# DSS0_WB register map
Vendor: Texas Instruments
Peripheral module from a debugger description file (folder J7ES).
Registers are 32-bit, access per field, reset 0x0 unless marked. A register's access mark holds for its fields unless they carry their own. Offsets are as the file gives them; lines under a group give offsets from that group; [hi:lo] are bit positions; {n}, {i} and the like mark numbered series; 'fields as' and 'values as' point back to an identical list; <NAME> marks a mode.

## DSS0_WB
0x00 DSS0_WB_ACCUH_0 — The register configures the resize accumulator init values for horizontal up/down-sampling of the write-back window. It is used for ARGB and Y setting. Shadow register
  [23:0] HORIZONTALACCU rw — Horizontal initialization accu signed value
0x04 DSS0_WB_ACCUH_1 — The register configures the resize accumulator init values for horizontal up/down-sampling of the write-back window. It is used for ARGB and Y setting. Shadow register
  fields as DSS0_WB_ACCUH_0
0x08 DSS0_WB_ACCUH2_0 — The register configures the resize accumulator init value for horizontal up/down-sampling of the write-back window. It is used for Cb and Cr setting. It is used only when the pixel format at the input of the filter is one of the YUV formats. If the pixel format at the input of the filter is ARGB, all ARGB, RGB, RGBA are converted to ARGB32-8888 by the color space conversion before going to the filter as the color space conversion is done before the filter. When the register is not used by the HW, any value can be used for the bit-fields. Shadow register
  fields as DSS0_WB_ACCUH_0
0x0C DSS0_WB_ACCUH2_1 — The register configures the resize accumulator init value for horizontal up/down-sampling of the write-back window. It is used for Cb and Cr setting. It is used only when the pixel format at the input of the filter is one of the YUV formats. If the pixel format at the input of the filter is ARGB, all ARGB, RGB, RGBA are converted to ARGB32-8888 by the color space conversion before going to the filter as the color space conversion is done before the filter. When the register is not used by the HW, any value can be used for the bit-fields. Shadow register
  fields as DSS0_WB_ACCUH_0
0x10 DSS0_WB_ACCUV_0 — The register configures the resize accumulator init value for vertical up/down-sampling of the write-back window. It is used for ARGB and Y setting. Shadow register
  [23:0] VERTICALACCU rw — Vertical initialization accu signed value
0x14 DSS0_WB_ACCUV_1 — The register configures the resize accumulator init value for vertical up/down-sampling of the write-back window. It is used for ARGB and Y setting. Shadow register
  [23:0] VERTICALACCU rw — Vertical initialization accu signed value
0x18 DSS0_WB_ACCUV2_0 — The register configures the resize accumulator init value for vertical up/down-sampling of the write-back window. It is used for Cb and Cr setting. It is used only when the pixel format at the input of the filter is one of the YUV formats. If the pixel format at the input of the filter is ARGB, all ARGB, RGB, RGBA are converted to ARGB32-8888 by the color space conversion before going to the filter as the color space conversion is done before the filter. When the register is not used by the HW, any value can be used for the bit-fields. Shadow register
  [23:0] VERTICALACCU rw — Vertical initialization accu signed value
0x1C DSS0_WB_ACCUV2_1 — The register configures the resize accumulator init value for vertical up/down-sampling of the write-back window. It is used for Cb and Cr setting. It is used only when the pixel format at the input of the filter is one of the YUV formats. If the pixel format at the input of the filter is ARGB, all ARGB, RGB, RGBA are converted to ARGB32-8888 by the color space conversion before going to the filter as the color space conversion is done before the filter. When the register is not used by the HW, any value can be used for the bit-fields. Shadow register
  [23:0] VERTICALACCU rw — Vertical initialization accu signed value
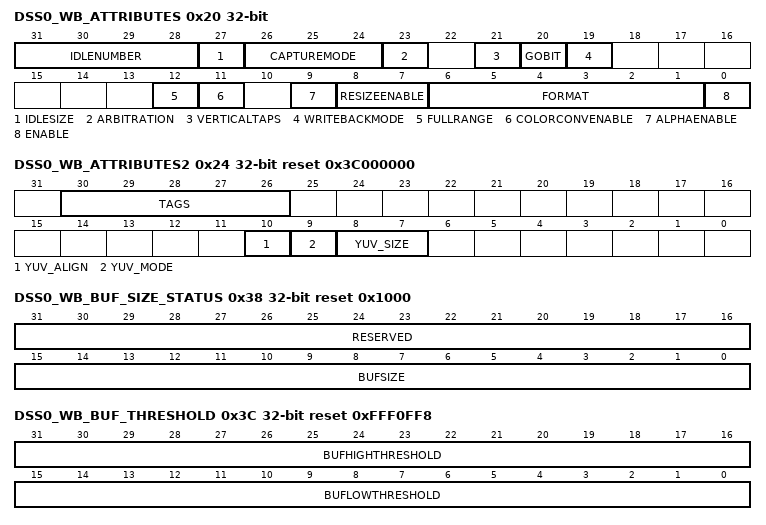
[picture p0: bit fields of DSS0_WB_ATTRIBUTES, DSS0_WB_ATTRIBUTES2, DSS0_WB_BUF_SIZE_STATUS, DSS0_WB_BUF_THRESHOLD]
0x20 DSS0_WB_ATTRIBUTES — The register configures the of the write back pipeline. Shadow register
  [31:28] IDLENUMBER rw — Determines the number of idles between requests on the L3 interconnect.
  [27] IDLESIZE rw — Determines if the IDLENUMBER corresponds to a number of bursts or singles
  [26:24] CAPTUREMODE rw — Defines the frame rate capture
  [23] ARBITRATION rw — Determines the priority of the write-back pipeline.
  [21] VERTICALTAPS rw — Video Vertical Resize Tap Number
  [20] GOBIT rw — GO Command for the WB output.
  [19] WRITEBACKMODE rw — When connected to the overlay output of a channel the write back can operate as a simple transfer from memory to memory [composition engine] or as a capture channel
  [12] FULLRANGE rw — Color Space Conversion full range setting
  [11] COLORCONVENABLE rw — Enable the color space conversion.
  [9] ALPHAENABLE rw — Alpha enable on WB output
  [8:7] RESIZEENABLE rw
  [6:1] FORMAT rw — Write-back Format.
  [0] ENABLE rw — Write-back Enable wr: immediate
0x24 DSS0_WB_ATTRIBUTES2 reset 0x3C000000 — The register configures the of the write back pipeline. Shadow register
  [30:26] TAGS rw — Number of OCP TAGS to be used for the pipeline [0x0 to 0xF].
  [10] YUV_ALIGN rw — Alignment [MSB or LSB align] for unpacked 10b/12b YUV data
  [9] YUV_MODE rw — Mode of packing for YUV data [only for 10b/12b formats]
  [8:7] YUV_SIZE rw
0x28 DSS0_WB_BA_0 rw — The register configures the base address of the WB buffer. DISPC_WB_BA__0 & DISPC_WB_BA__1 for ping-pong mechanism with external trigger, based on the field polarity, otherwise only DISPC_WB_BA__0 is used. Shadow register
  [31:0] BA — Write-back base address Base address of the WB buffer [aligned on pixel
0x2C DSS0_WB_BA_1 rw — The register configures the base address of the WB buffer. DISPC_WB_BA__0 & DISPC_WB_BA__1 for ping-pong mechanism with external trigger, based on the field polarity, otherwise only DISPC_WB_BA__0 is used. Shadow register
  fields as DSS0_WB_BA_0
0x30 DSS0_WB_BA_UV_0 rw — The register configures the base address of the UV buffer for the write-back pipeline. DISPC_WB_BA_UV__0 & DISPC_WB_BA_UV__1 for ping-pong mechanism with external trigger, based on the field polarity, otherwise only DISPC_WB_BA_UV__0 is used. The register is also used to configure the RGB plane BA for RGB565A8 format. Shadow register
  [31:0] BA — WB base address aligned on 16-bit boundary.
0x34 DSS0_WB_BA_UV_1 rw — The register configures the base address of the UV buffer for the write-back pipeline. DISPC_WB_BA_UV__0 & DISPC_WB_BA_UV__1 for ping-pong mechanism with external trigger, based on the field polarity, otherwise only DISPC_WB_BA_UV__0 is used. The register is also used to configure the RGB plane BA for RGB565A8 format. Shadow register
  [31:0] BA — WB base address aligned on 16-bit boundary.
0x38 DSS0_WB_BUF_SIZE_STATUS ro reset 0x1000 — The register defines the DMA buffer for the write back pipeline
  [31:16] RESERVED — Write 0's for future compatibility.
  [15:0] BUFSIZE — DMA buffer
0x3C DSS0_WB_BUF_THRESHOLD rw reset 0xFFF0FF8 — The register configures the DMA buffer associated with the write-back pipeline. Shadow register
  [31:16] BUFHIGHTHRESHOLD — DMA buffer High Threshold Number of
  [15:0] BUFLOWTHRESHOLD — DMA buffer High Threshold Number of
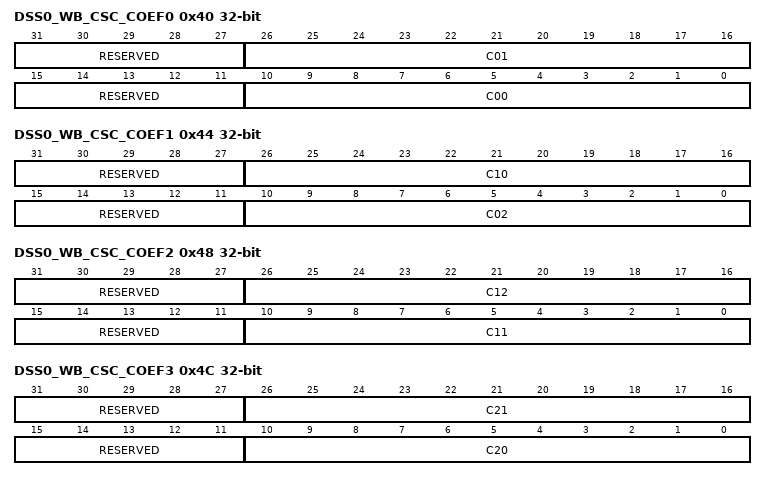
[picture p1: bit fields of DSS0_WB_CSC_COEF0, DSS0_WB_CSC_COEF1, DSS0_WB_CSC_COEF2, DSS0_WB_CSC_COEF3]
0x40 DSS0_WB_CSC_COEF0 — The register configures the color space conversion matrix coefficients. Shadow register
  [31:27] RESERVED ro — Write 0's for future compatibility Reads return 0
  [26:16] C01 rw — C01 Coefficient.
  [15:11] RESERVED ro — Write 0's for future compatibility Reads return 0
  [10:0] C00 rw — C00 Coefficient.
0x44 DSS0_WB_CSC_COEF1 — The register configures the color space conversion matrix coefficients. Shadow register
  [31:27] RESERVED ro — Write 0's for future compatibility Reads return 0
  [26:16] C10 rw — C10 Coefficient.
  [15:11] RESERVED ro — Write 0's for future compatibility Reads return 0
  [10:0] C02 rw — C02 Coefficient.
0x48 DSS0_WB_CSC_COEF2 — The register configures the color space conversion matrix coefficients. Shadow register
  [31:27] RESERVED ro — Write 0's for future compatibility Reads return 0
  [26:16] C12 rw — C12 Coefficient.
  [15:11] RESERVED ro — Write 0's for future compatibility Reads return 0
  [10:0] C11 rw — C11 Coefficient.
0x4C DSS0_WB_CSC_COEF3 — The register configures the color space conversion matrix coefficients. Shadow register
  [31:27] RESERVED ro — Write 0's for future compatibility Reads return 0
  [26:16] C21 rw — C21 coefficient.
  [15:11] RESERVED ro — Write 0's for future compatibility Reads return 0
  [10:0] C20 rw — C20 coefficient.
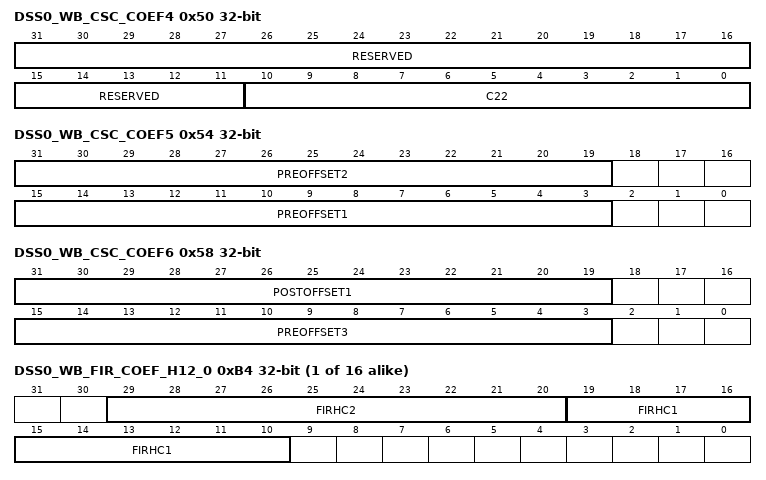
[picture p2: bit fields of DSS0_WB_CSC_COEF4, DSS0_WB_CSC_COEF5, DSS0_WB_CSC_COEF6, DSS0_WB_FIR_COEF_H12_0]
0x50 DSS0_WB_CSC_COEF4 — The register configures the color space conversion matrix coefficients. Shadow register
  [31:11] RESERVED ro — Write 0's for future compatibility Reads return 0
  [10:0] C22 rw — C22 Coefficient.
0x54 DSS0_WB_CSC_COEF5 — The register configures the color space conversion matrix coefficients. Shadow register
  [31:19] PREOFFSET2 rw — Row-2 pre-offset.
  [15:3] PREOFFSET1 rw — Row1 pre-offset.
0x58 DSS0_WB_CSC_COEF6 — The register configures the color space conversion matrix coefficients. Shadow register
  [31:19] POSTOFFSET1 rw — Row-1 post-offset.
  [15:3] PREOFFSET3 rw — Row-3 pre-offset.
0x5C DSS0_WB_FIRH reset 0x200000 — The register configures the resize factor for horizontal up/down-sampling of the write-back window. It is used for ARGB and Y setting. Shadow register
  [23:0] FIRHINC rw — Horizontal increment of the up/down-sampling filter.
0x60 DSS0_WB_FIRH2 reset 0x200000 — The register configures the resize factor for horizontal up/down-sampling of the write-back window. It is used for Crb and Cr setting. It is used only when the pixel format at the input of the filter is one of the YUV formats. If the pixel format at the input of the filter is ARGB all ARGB, RGB, RGBA are converted to ARGB32-8888 by the color space conversion before going to the filter is the color space conversion is done before the filter. When the register is not used by the HW, any value can be used for the bit-fields. Shadow register
  [23:0] FIRHINC rw — Horizontal increment of the up/down-sampling filter for Cb and Cr.
0x64 DSS0_WB_FIRV reset 0x200000 — The register configures the resize factor for vertical up/down-sampling of the write-back window. It is used for ARGB and Y setting. Shadow register
  [23:0] FIRVINC rw — Vertical increment of the up/down-sampling filter.
0x68 DSS0_WB_FIRV2 reset 0x200000 — The register configures the resize factor for vertical up/down-sampling of the write-back window. It is used for Crb and Cr setting. It is used only when the pixel format at the input of the filter is one of the YUV formats. If the pixel format at the input of the filter is ARGB all ARGB, RGB, RGBA are converted to ARGB32-8888 by the color space conversion before going to the filter is the color space conversion is done before the filter. When the register is not used by the HW, any value can be used for the bit-fields. Shadow register
  [23:0] FIRVINC rw — Vertical increment of the up/down-sampling filter for Cb and Cr.
{0x6C+4i} DSS0_WB_FIR_COEF_H0_{i} (i=0..8) — The bank of registers configures the up/down-scaling coefficients for the horizontal resize of the video picture associated with the write back pipeline for the phases from 0 to 15. It is used for ARGB and Y setting. Shadow register
  [9:0] FIRHC0 rw — Unsigned coefficient C0 for the horizontal up/down-scaling with the phase n
{0x90+4i} DSS0_WB_FIR_COEF_H0_C_{i} (i=0..8) — The bank of registers configures the up/down-scaling coefficients for the horizontal resize of the video picture associated with the write back pipeline for the phases from 0 to 15. It is used for Crb and Cr setting. It is used only when the pixel format at the input of the filter is one of the YUV formats. If the pixel format at the input of the filter is ARGB all ARGB, RGB, RGBA are converted to ARGB32-8888 by the color space conversion before going to the filter is the color space conversion is done before the filter. When the register is not used by the HW, any value can be used for the bit-fields. Shadow register
  fields as DSS0_WB_FIR_COEF_H0_0
{0xB4+4i} DSS0_WB_FIR_COEF_H12_{i} (i=0..15) — The bank of registers configures the up/down-scaling coefficients for the horizontal resize of the video picture associated with the write back pipeline for the phases from 0 to 15. It is used for ARGB and Y setting. Shadow register
  [29:20] FIRHC2 rw — Signed coefficient C2 for the horizontal up/down-scaling with the phase n
  [19:10] FIRHC1 rw — Signed coefficient C1 for the horizontal up/down-scaling with the phase n
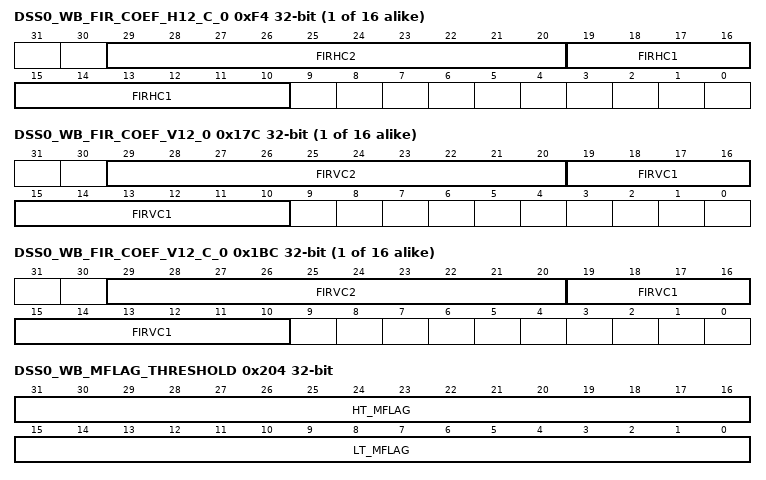
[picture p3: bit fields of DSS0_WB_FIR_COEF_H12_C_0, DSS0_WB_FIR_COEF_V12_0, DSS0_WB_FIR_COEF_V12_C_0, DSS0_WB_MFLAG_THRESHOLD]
{0xF4+4i} DSS0_WB_FIR_COEF_H12_C_{i} (i=0..15) — The bank of registers configures the up/down-scaling coefficients for the horizontal resize of the video picture associated with the write back pipeline for the phases from 0 to 15. It is used for Crb and Cr setting. It is used only when the pixel format at the input of the filter is one of the YUV formats. If the pixel format at the input of the filter is ARGB all ARGB, RGB, RGBA are converted to ARGB32-8888 by the color space conversion before going to the filter is the color space conversion is done before the filter. When the register is not used by the HW, any value can be used for the bit-fields. Shadow register
  fields as DSS0_WB_FIR_COEF_H12_0
{0x134+4i} DSS0_WB_FIR_COEF_V0_{i} (i=0..8) — The bank of registers configures the down/up/down-scaling coefficients for the vertical resize of the video picture associated with the write back pipeline for the phases from 0 to 15. It is used for ARGB and Y setting. Shadow register
  [9:0] FIRVC0 rw — Unsigned coefficient C0 for the vertical up/down-scaling with the phase n
{0x158+4i} DSS0_WB_FIR_COEF_V0_C_{i} (i=0..8) — The bank of registers configures the down/up/down-scaling coefficients for the vertical resize of the video picture associated with the write back pipeline for the phases from 0 to 15. It is used for Crb and Cr setting. It is used only when the pixel format at the input of the filter is one of the YUV formats. If the pixel format at the input of the filter is ARGB all ARGB, RGB, RGBA are converted to ARGB32-8888 by the color space conversion before going to the filter is the color space conversion is done before the filter. When the register is not used by the HW, any value can be used for the bit-fields. Shadow register
  fields as DSS0_WB_FIR_COEF_V0_0
{0x17C+4i} DSS0_WB_FIR_COEF_V12_{i} (i=0..15) — The bank of registers configures the down/up/down-scaling coefficients for the vertical resize of the video picture associated with the write back pipeline for the phases from 0 to 15. It is used for ARGB and Y setting. Shadow register
  [29:20] FIRVC2 rw — Signed coefficient C2 for the vertical up/down-scaling with the phase n
  [19:10] FIRVC1 rw — Signed coefficient C1 for the vertical up/down-scaling with the phase n
{0x1BC+4i} DSS0_WB_FIR_COEF_V12_C_{i} (i=0..15) — The bank of registers configures the down/up/down-scaling coefficients for the vertical resize of the video picture associated with the write back pipeline for the phases from 0 to 15. It is used for Crb and Cr setting. It is used only when the pixel format at the input of the filter is one of the YUV formats. If the pixel format at the input of the filter is ARGB all ARGB, RGB, RGBA are converted to ARGB32-8888 by the color space conversion before going to the filter is the color space conversion is done before the filter. When the register is not used by the HW, any value can be used for the bit-fields. Shadow register
  fields as DSS0_WB_FIR_COEF_V12_0
0x204 DSS0_WB_MFLAG_THRESHOLD rw — Register
  [31:16] HT_MFLAG — MFlag High Threshold
  [15:0] LT_MFLAG — MFlag Low Threshold
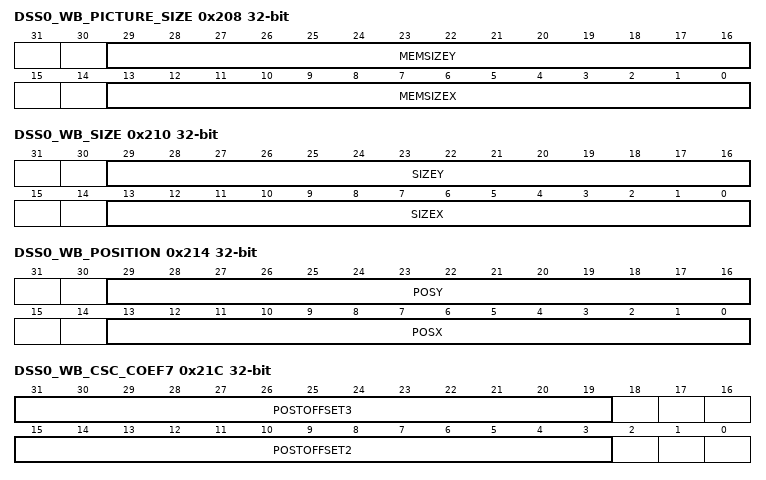
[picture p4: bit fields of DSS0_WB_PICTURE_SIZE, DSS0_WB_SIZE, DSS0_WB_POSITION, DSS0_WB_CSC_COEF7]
0x208 DSS0_WB_PICTURE_SIZE rw — The register configures the of the write-back picture associated with the write back pipeline after up/down-scaling of the image stored in DDR memory, generated by WB pipe. Shadow register
  [29:16] MEMSIZEY — Number of lines of the wb picture in memory Encoded value [from 1 to 16384] to specify the number of lines of the picture store in memory [program to value minus one]
  [13:0] MEMSIZEX — Number of pixels of the wb picture in memory Encoded value [from 1 to 16384] to specify the number of pixels of the picture stored in memory [program to value minus one]
0x210 DSS0_WB_SIZE rw — The register configures the of the output of overlay connected to the write-back pipeline when the overlay output is only used by the write-back pipeline. When the overlay is output on the primary LCD or secondary LCD or TV outputs, the of the frame is defined in the DISPC_SIZE_LCD1, DISPC_SIZE_LCD2, and DISPC_SIZE_TV respectively. Shadow register.
  [29:16] SIZEY — Number of lines of the Write-back picture Encoded value [from 1 to 16384] to specify the number of lines of the write-back picture from overlay or pipeline
  [13:0] SIZEX — Number of pixels of the Write-back picture Encoded value [from 1 to 16384] to specify the number of pixels of the write-back picture from overlay or pipeline
0x214 DSS0_WB_POSITION — The register configures the start of the window on overlay which wb will capture. Shadow register. Only applicable when WB is operating in capture_mode
  [29:16] POSY rw — Y
  [13:0] POSX rw — X
0x21C DSS0_WB_CSC_COEF7 — The register configures the color space conversion matrix coefficients. Shadow register
  [31:19] POSTOFFSET3 rw — Row-3 post-offset.
  [15:3] POSTOFFSET2 rw — Row-2 post-offset.
0x224 DSS0_WB_ROW_INC rw reset 0x1 — The register configures the number of bytes to increment at the end of the row for the buffer associated with the WB window. For YUV420 formats this corresponds to the Y Buffer Shadow register.
  [31:0] ROWINC — Number of bytes to increment at the end of the row Encoded signed value [from -2
0x228 DSS0_WB_ROW_INC_UV rw reset 0x1 — The register configures the number of bytes to increment at the end of the row for the UV buffer associated with the WB window for YUV420 formats. For non-YUV420 formats this register is unused. Shadow register
  fields as DSS0_WB_ROW_INC
0x22C DSS0_WB_BA_EXT_0 — The register configures the 16-bit base address extension. It is the base-address of the single video buffer for single plane ARGB or YUV. For the Y buffer for two plane YUV. For the Alpha buffer for two plane RGB565-A8. 0 & 1 : For ping-pong mechanism with external trigger, based on the field polarity. Shadow register
  [15:0] BA_EXT rw — Video base address extension [16 bits].
0x230 DSS0_WB_BA_EXT_1 — The register configures the 16-bit base address extension. It is the base-address of the single video buffer for single plane ARGB or YUV. For the Y buffer for two plane YUV. For the Alpha buffer for two plane RGB565-A8. 0 & 1 : For ping-pong mechanism with external trigger, based on the field polarity. Shadow register
  [15:0] BA_EXT rw — Video base address extension [16 bits].
0x234 DSS0_WB_BA_UV_EXT_0 — The register configures the 16-bit base address extension of the UV buffer for two plane YUV or the RGB buffer for two plane RGB565-A8. 0 & 1 : For ping-pong mechanism with external trigger, based on the field polarity. Shadow register
  [15:0] BA_UV_EXT rw — Video base address extension [16 bits].
0x238 DSS0_WB_BA_UV_EXT_1 — The register configures the 16-bit base address extension of the UV buffer for two plane YUV or the RGB buffer for two plane RGB565-A8. 0 & 1 : For ping-pong mechanism with external trigger, based on the field polarity. Shadow register
  [15:0] BA_UV_EXT rw — Video base address extension [16 bits].
0x248 DSS0_WB_SECURE — Security bit settings for the sub-module
  [0] SECURE rw
